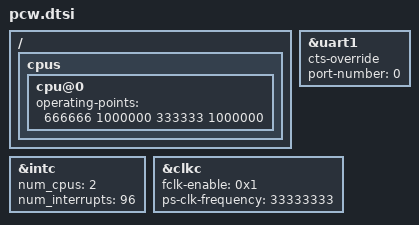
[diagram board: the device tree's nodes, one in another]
/*
 * CAUTION: This file is automatically generated by Xilinx.
 * Version: XSCT 2020.2
 * Today is: Wed Oct 13 14:26:41 2021
 */


/ {
	cpus {
		cpu@0 {
			operating-points = <666666 1000000 333333 1000000>;
		};
	};
};
&intc {
	num_cpus = <2>;
	num_interrupts = <96>;
};
&uart1 {
	cts-override ;
	device_type = "serial";
	port-number = <0>;
	status = "okay";
};
&clkc {
	fclk-enable = <0x1>;
	ps-clk-frequency = <33333333>;
};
